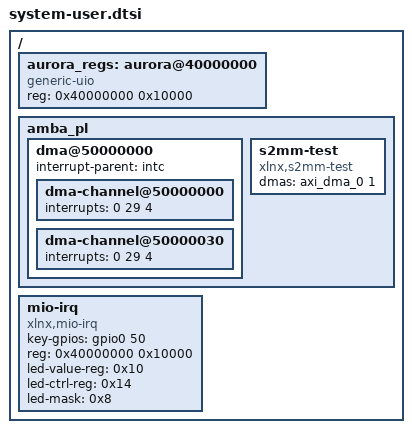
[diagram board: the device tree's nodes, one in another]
/include/ "system-conf.dtsi"
/ {
	/*
	 * aurora 手写寄存器窗口 (PL, 0x40000000 / 64 KiB)。
	 * Vivado/PetaLinux 自动生成的 pl.dtsi 不会为外部主端口 M00_AXI 背后的
	 * 手写 RTL 出节点，故在此手动声明 generic-uio:
	 *   - compatible "generic-uio" 由内核 uio_pdrv_genirq 驱动绑定
	 *     (CONFIG_UIO_PDRV_GENIRQ, 需 modprobe uio_pdrv_genirq 才挂载)
	 *   - Zynq-7000 root #address-cells=<1>, 故 reg = <基址 尺寸>
	 *   - 用户态 mmap(fd, NUMPAGES*PAGE_SIZE, ..., MAP_SHARED, /dev/uio0, 0)
	 *     后偏移即窗内寄存器 (SCRATCH@0x00 / VERSION@0x04 / CTRL@0x08、
	 *     LED_VALUE@0x10 / LED_CTRL@0x14 / LED_STATUS@0x18 等, 见 aurora_regs.h)
	 */
	aurora_regs: aurora@40000000 {
		compatible = "generic-uio";
		reg = <0x40000000 0x10000>;
	};

	/*
	 * 兜底补中断:DTG 无法穿透 PL 的 util_vector_logic(OR 门) 为 AXI DMA 计算中断号,
	 * 导致 dma-channel 缺 interrupts,驱动会因 irq=0 而 probe 失败(见 xilinx_dma_request_irq)。
	 * AXI DMA 的 MM2S/S2MM 两路中断在 PL 内经 OR 门并入 IRQ_F2P[0] =>
	 * Zynq-7000 GIC SPI 61(本板编码下 dts 写 29 即映射到该 SPI),高电平有效(type 4)。两 channel 共享该一路中断,
	 * xilinx_dma 驱动以 IRQF_SHARED 请求,兼容共享。
	 */
	amba_pl {
		dma@50000000 {
			/* amba_pl 与根 /. 都无 interrupt-parent；不给它补上，
			 * irq_of_parse_and_map 将解析不到 GIC 而回落到 0 →
			 * request_irq(0) 失败，channel 不注册。intc 为现存 label。 */
			interrupt-parent = <&intc>;
			dma-channel@50000000 {
				interrupts = <0 29 4>;
				interrupt-names = "irq_mm2s";
			};
			dma-channel@50000030 {
				interrupts = <0 29 4>;
				interrupt-names = "irq_s2mm";
			};
		};

		/* AXI-DMA S2MM dmaengine 客户节点:绑定 xlnx_s2mm_test.ko。
		 * dmas = <&axi_dma_0 1>: args[0]=1 -> S2MM 通道
		 * (chan->id=1, tdest=1-max/2=0 -> 取 interrupts[0]=SPI61 这三个字段中的第二个,
		 * 与 XILINX_DMA_MAX_CHANS_PER_DEVICE=2 (s2mm_chan_id 从 max/2=1 起) 一致。 */
		s2mm-test {
			compatible = "xlnx,s2mm-test";
			dmas = <&axi_dma_0 1>;
			dma-names = "s2mm_channel";
		};
	};

	/* ===== MIO50 按键中断 → PL LED 翻转 demo（MLK-F6P-CZ05 / XC7Z015 版）=====
	 *
	 * 新板为什么不用 MIO51 当 PS 侧 LED：
	 *   手册 "12:千兆网口" 把 MIO51 标成网口(PHY)复位，"24:LED" 表和厂商例程 DTS
	 *   又把它当 PS LED —— 资料自相矛盾(见 fpga 仓库 docs/board-io-peripherals.md §4)。
	 *   无论如何接线，PS7 里 ENET0 复位就挂在 MIO51(PCW_ENET0_RESET_IO = MIO 51)，
	 *   Linux 把它当 LED 翻转 = 一直按住 PHY 复位 → "系统起来但没有网口"
	 *   (旧板 F6-7020 的 S99psled-off 就是这么把网口弄没的)。
	 *
	 * 所以本 demo 改成：**PS 只负责按键中断，输出落到 PL 的 LED**，
	 * 即 MIO50(底板 PS 按键, 下降沿) --中断--> 写 aurora 寄存器窗
	 *      → LED_VALUE(0x10)/LED_CTRL(0x14) → 翻 PL 的 led_o[0] (U16 = 底板 LED3)
	 *
	 * reg 指的 0x40000000/64K 与上面的 aurora@40000000(generic-uio) 是同一块物理窗:
	 *   UIO 供用户态(fpga 工具 mmap), 本模块在内核态 ioremap 同一窗口写 LED 寄存器。
	 *   MIO50 未被任何 PS 外设占用(ETH0=16..27/51/52/53, USB0=28..39/46,
	 *   SD0=40..45/47, SD1=10..15, UART1=48/49, QSPI=1..6/8)，天生就是 GPIO 且
	 *   落在 zynq-gpio 支持中断的 MIO 组里(0..15 / 50..53)。
	 */
	mio-irq {
		compatible = "xlnx,mio-irq";
		key-gpios = <&gpio0 50 0>;   /* PS_MIO50 -> 底板 PS 按键(上拉+RC, 按下=低) */
		reg = <0x40000000 0x10000>;   /* PL aurora 寄存器窗(PS 视角, M_AXI_GP0 基址) */
		led-value-reg = <0x10>;       /* LED_VALUE: [3:0] 点亮哪几颗 */
		led-ctrl-reg = <0x14>;        /* LED_CTRL : bit0 = 使能 */
		led-mask = <0x8>;             /* 点亮 丝印 LED1 = H8 = 本工程 led_o[3] */
		                              /* (位号与引脚顺序相反: bit0=U16,bit1=AB21,bit2=T16,bit3=H8) */
	};
};
